# STM32U5A9xx register map
File version: 1.0
Registers are 32-bit, read-write, reset 0x0 unless marked. A register's access mark holds for its fields unless they carry their own. Offsets are from the block's base; [hi:lo] are bit positions; {n}, {i} and the like mark numbered series.

## DSI — DSI Controller
Base 0x40016C00
Same registers: DSI_S 0x50016C00
0x00 VR — DSI Host Version Register
  [31:0] VR — DSI Host Version 0x3134312A
0x04 CR — DSI Host Control Register
  [0] EN — DSI Host power up and reset
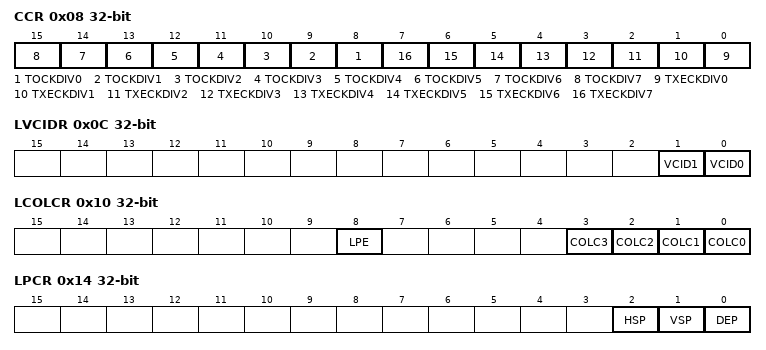
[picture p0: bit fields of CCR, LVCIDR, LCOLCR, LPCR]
0x08 CCR — DSI HOST Clock Control Register
  [n+8] TOCKDIV{n} (n=0..7), [n] TXECKDIV{n} (n=0..7)
0x0C LVCIDR — DSI Host LTDC VCID Register
  [1] VCID1, [0] VCID0
0x10 LCOLCR — DSI Host LTDC Color Coding Register
  [8] LPE — Loosely Packet Enable
  [n] COLC{n} (n=0..3)
0x14 LPCR — DSI Host LTDC Polarity Configuration Register
  [2] HSP — HSYNC Polarity
  [1] VSP — VSYNC Polarity
  [0] DEP — Data Enable Polarity
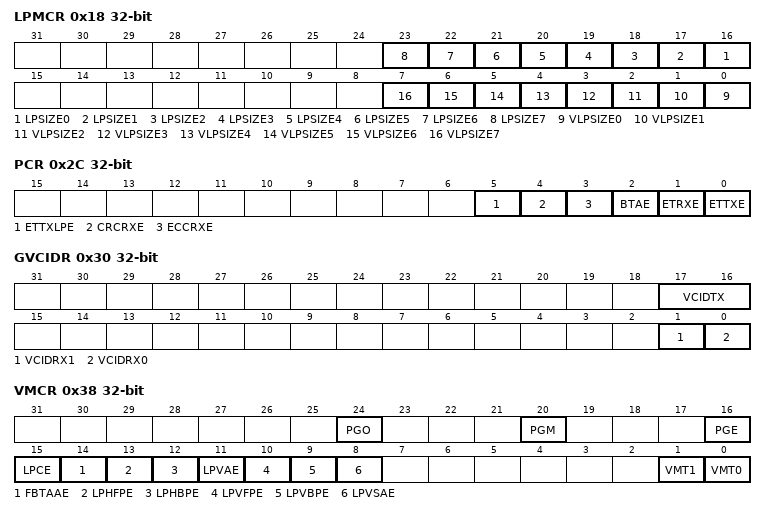
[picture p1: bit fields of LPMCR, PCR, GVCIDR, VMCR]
0x18 LPMCR — DSI Host Low-Power Mode Configuration Register
  [n+16] LPSIZE{n} (n=0..7), [n] VLPSIZE{n} (n=0..7)
0x2C PCR — DSI Host Protocol Configuration Register
  [5] ETTXLPE — EoTp Transmission in Low-Power Enable
  [4] CRCRXE — CRC Reception Enable
  [3] ECCRXE — ECC Reception Enable
  [2] BTAE — Bus Turn Around Enable
  [1] ETRXE — EoTp Reception Enable
  [0] ETTXE — EoTp Transmission Enable
0x30 GVCIDR — DSI Host Generic VCID Register
  [17:16] VCIDTX — Virtual Channel ID for Transmission
  [1] VCIDRX1
  [0] VCIDRX0
0x34 MCR — DSI Host Mode Configuration Register
  [0] CMDM — Command Mode
0x38 VMCR — DSI Host Video Mode Configuration Register
  [24] PGO — Pattern Generator Orientation
  [20] PGM — Pattern Generator Mode
  [16] PGE — Pattern Generator Enable
  [15] LPCE — Low-Power Command Enable
  [14] FBTAAE — Frame Bus-Turn-Around Acknowledge Enable
  [13] LPHFPE — Low-Power Horizontal Front-Porch Enable
  [12] LPHBPE — Low-Power Horizontal Back-Porch Enable
  [11] LPVAE — Low-Power Vertical Active Enable
  [10] LPVFPE — Low-power Vertical Front-porch Enable
  [9] LPVBPE — Low-power Vertical Back-Porch Enable
  [8] LPVSAE — Low-Power Vertical Sync Active Enable
  [1] VMT1
  [0] VMT0
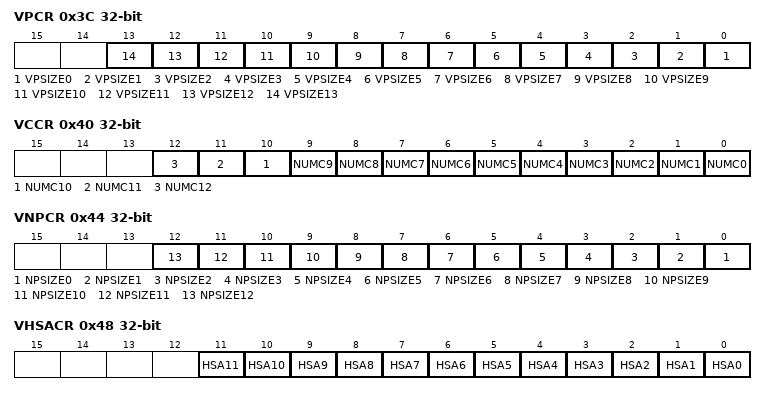
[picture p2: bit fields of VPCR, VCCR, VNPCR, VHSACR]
0x3C VPCR — DSI Host Video Packet Configuration Register
  [n] VPSIZE{n} (n=0..13)
0x40 VCCR — DSI Host Video Chunks Configuration Register
  [n] NUMC{n} (n=0..12)
0x44 VNPCR — DSI Host Video Null Packet Configuration Register
  [n] NPSIZE{n} (n=0..12)
0x48 VHSACR — DSI Host Video HSA Configuration Register
  [n] HSA{n} (n=0..11)
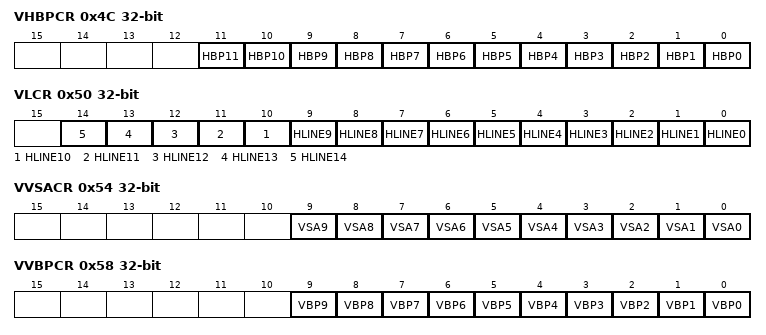
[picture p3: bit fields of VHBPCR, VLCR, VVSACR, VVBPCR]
0x4C VHBPCR — DSI Host Video HBP Configuration Register
  [n] HBP{n} (n=0..11)
0x50 VLCR — DSI Host Video Line Configuration Register
  [n] HLINE{n} (n=0..14)
0x54 VVSACR — DSI Host Video VSA Configuration Register
  [n] VSA{n} (n=0..9)
0x58 VVBPCR — DSI Host Video VBP Configuration Register
  [n] VBP{n} (n=0..9)
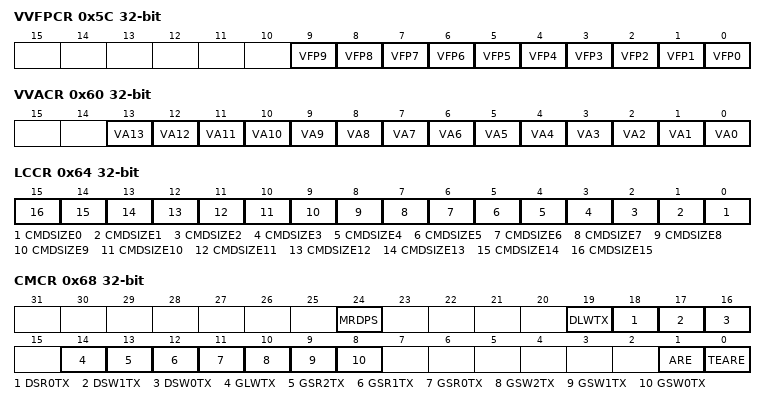
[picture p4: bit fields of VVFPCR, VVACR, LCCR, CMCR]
0x5C VVFPCR — DSI Host Video VFP Configuration Register
  [n] VFP{n} (n=0..9)
0x60 VVACR — DSI Host Video VA Configuration Register
  [n] VA{n} (n=0..13)
0x64 LCCR — DSI Host LTDC Command Configuration Register
  [n] CMDSIZE{n} (n=0..15)
0x68 CMCR — DSI Host Command Mode Configuration Register
  [24] MRDPS — Maximum Read Packet Size
  [19] DLWTX — DCS Long Write Transmission
  [18] DSR0TX — DCS Short Read Zero parameter Transmission
  [17] DSW1TX — DCS Short Read One parameter Transmission
  [16] DSW0TX — DCS Short Write Zero parameter Transmission
  [14] GLWTX — Generic Long Write Transmission
  [13] GSR2TX — Generic Short Read Two parameters Transmission
  [12] GSR1TX — Generic Short Read One parameters Transmission
  [11] GSR0TX — Generic Short Read Zero parameters Transmission
  [10] GSW2TX — Generic Short Write Two parameters Transmission
  [9] GSW1TX — Generic Short Write One parameters Transmission
  [8] GSW0TX — Generic Short Write Zero parameters Transmission
  [1] ARE — Acknowledge Request Enable
  [0] TEARE — Tearing Effect Acknowledge Request Enable
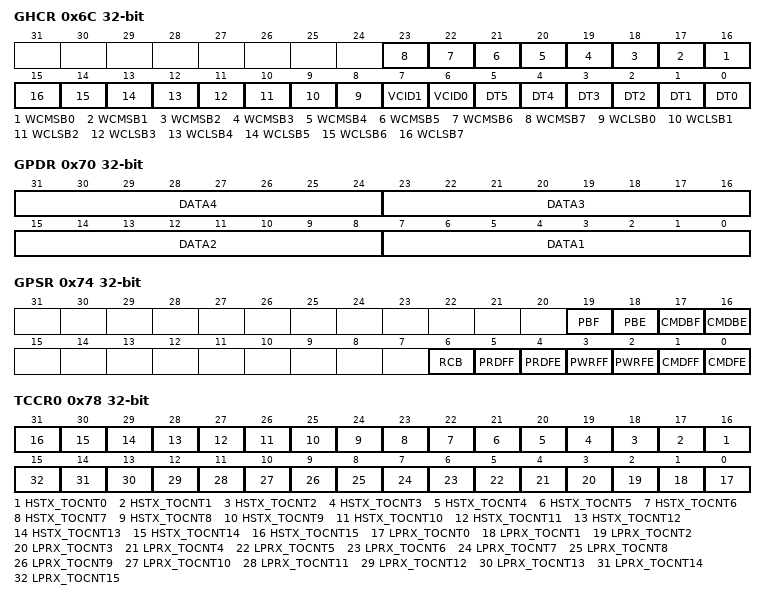
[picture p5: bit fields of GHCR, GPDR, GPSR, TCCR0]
0x6C GHCR — DSI Host Generic Header Configuration Register
  [n+16] WCMSB{n} (n=0..7), [n+8] WCLSB{n} (n=0..7), [7] VCID1, [6] VCID0, [n] DT{n} (n=0..5)
0x70 GPDR — DSI Host Generic Payload Data Register
  [8n-1:8n-8] DATA{n} (n=1..4) — Payload Byte {n}
0x74 GPSR — DSI Host Generic Packet Status Register
  [19] PBF — Payload Buffer Full
  [18] PBE — Payload Buffer Empty
  [17] CMDBF — Command Buffer Full
  [16] CMDBE — Command Buffer Empty
  [6] RCB — Read Command Busy
  [5] PRDFF — Payload Read FIFO Full
  [4] PRDFE — Payload Read FIFO Empty
  [3] PWRFF — Payload Write FIFO Full
  [2] PWRFE — Payload Write FIFO Empty
  [1] CMDFF — Command FIFO Full
  [0] CMDFE — Command FIFO Empty
0x78 TCCR0 — DSI Host Timeout Counter Configuration Register
  [n+16] HSTX_TOCNT{n} (n=0..15), [n] LPRX_TOCNT{n} (n=0..15)
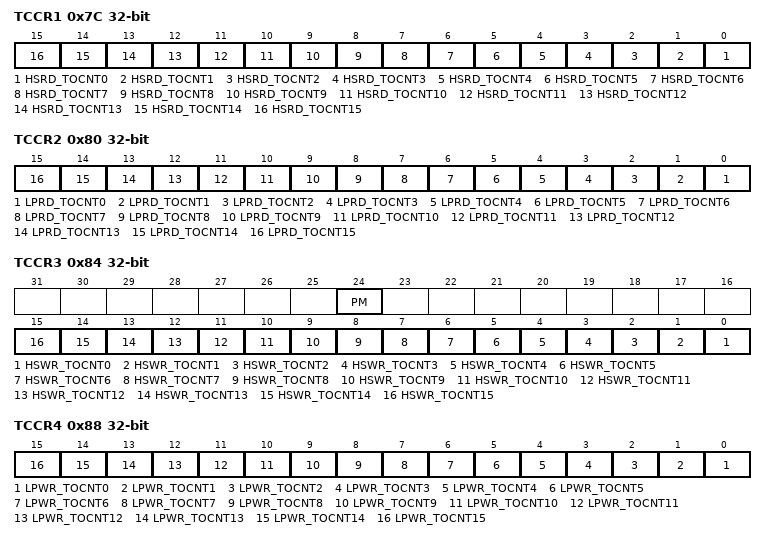
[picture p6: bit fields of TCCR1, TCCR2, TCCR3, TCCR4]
0x7C TCCR1 — DSI Host Timeout Counter Configuration Register
  [n] HSRD_TOCNT{n} (n=0..15)
0x80 TCCR2 — DSI Host Timeout Counter Configuration Register
  [n] LPRD_TOCNT{n} (n=0..15)
0x84 TCCR3 — DSI Host Timeout Counter Configuration Register
  [24] PM — Presp Mode
  [n] HSWR_TOCNT{n} (n=0..15)
0x88 TCCR4 — DSI Host Timeout Counter Configuration Register
  [n] LPWR_TOCNT{n} (n=0..15)
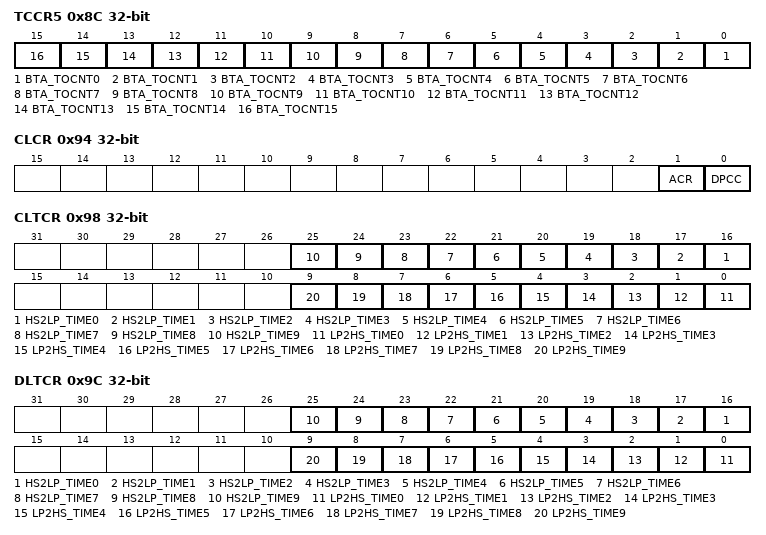
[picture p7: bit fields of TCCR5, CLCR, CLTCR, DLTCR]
0x8C TCCR5 — DSI Host Timeout Counter Configuration Register
  [n] BTA_TOCNT{n} (n=0..15)
0x94 CLCR — DSI Host Clock Lane Configuration Register
  [1] ACR — Automatic Clocklane Control
  [0] DPCC — D-PHY Clock Control
0x98 CLTCR — DSI Host Clock Lane Timer Configuration Register
  [n+16] HS2LP_TIME{n} (n=0..9), [n] LP2HS_TIME{n} (n=0..9)
0x9C DLTCR — DSI Host Data Lane Timer Configuration Register
  [n+16] HS2LP_TIME{n} (n=0..9), [n] LP2HS_TIME{n} (n=0..9)
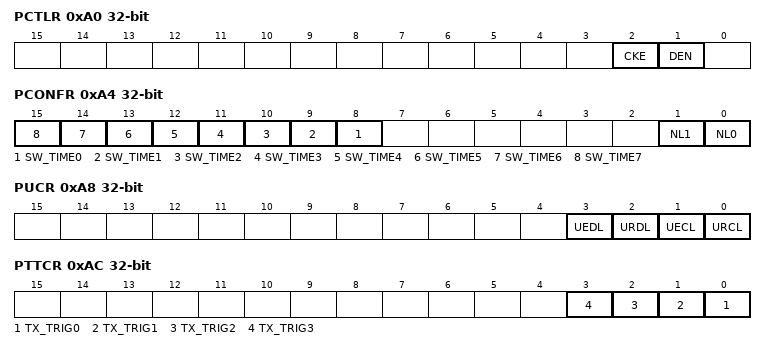
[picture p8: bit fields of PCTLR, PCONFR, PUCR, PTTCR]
0xA0 PCTLR — DSI Host PHY Control Register
  [2] CKE — Clock Enable
  [1] DEN — Digital Enable
0xA4 PCONFR — DSI Host PHY Configuration Register
  [n+8] SW_TIME{n} (n=0..7), [1] NL1, [0] NL0
0xA8 PUCR — DSI Host PHY ULPS Control Register
  [3] UEDL — ULPS Exit on Data Lane
  [2] URDL — ULPS Request on Data Lane
  [1] UECL — ULPS Exit on Clock Lane
  [0] URCL — ULPS Request on Clock Lane
0xAC PTTCR — DSI Host PHY TX Triggers Configuration Register
  [n] TX_TRIG{n} (n=0..3)
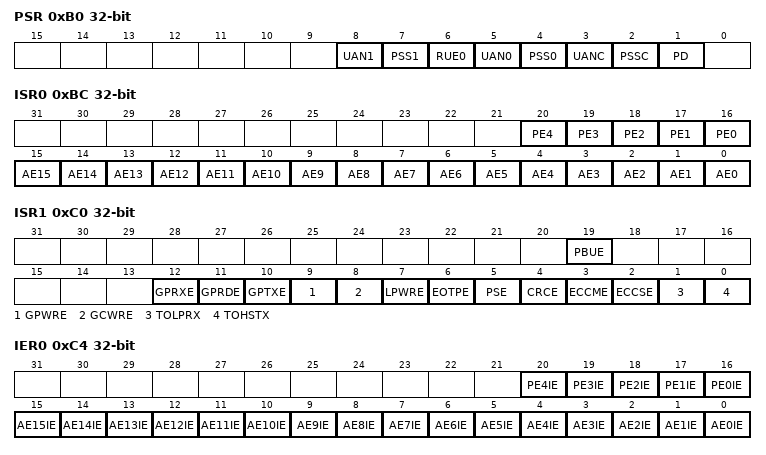
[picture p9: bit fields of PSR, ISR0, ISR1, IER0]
0xB0 PSR — DSI Host PHY Status Register
  [8] UAN1 — ULPS Active Not lane 1
  [7] PSS1 — PHY Stop State lane 1
  [6] RUE0 — RX ULPS Escape lane 0
  [5] UAN0 — ULPS Active Not lane 0
  [4] PSS0 — PHY Stop State lane 0
  [3] UANC — ULPS Active Not Clock lane
  [2] PSSC — PHY Stop State Clock lane
  [1] PD — PHY Direction
0xBC ISR0 — DSI Host Interrupt & Status Register
  [n+16] PE{n} (n=0..4) — PHY Error {n}
  [n] AE{n} (n=0..15) — Acknowledge Error {n}
0xC0 ISR1 — DSI Host Interrupt & Status Register
  [19] PBUE — Payload Buffer Underflow Error
  [12] GPRXE — Generic Payload Receive Error
  [11] GPRDE — Generic Payload Read Error
  [10] GPTXE — Generic Payload Transmit Error
  [9] GPWRE — Generic Payload Write Error
  [8] GCWRE — Generic Command Write Error
  [7] LPWRE — LTDC Payload Write Error
  [6] EOTPE — EoTp Error
  [5] PSE — Packet Size Error
  [4] CRCE — CRC Error
  [3] ECCME — ECC Multi-bit Error
  [2] ECCSE — ECC Single-bit Error
  [1] TOLPRX — Timeout Low-Power Reception
  [0] TOHSTX — Timeout High-Speed Transmission
0xC4 IER0 — DSI Host Interrupt Enable Register
  [n+16] PE{n}IE (n=0..4) — PHY Error {n} Interrupt Enable
  [n] AE{n}IE (n=0..15) — Acknowledge Error {n} Interrupt Enable
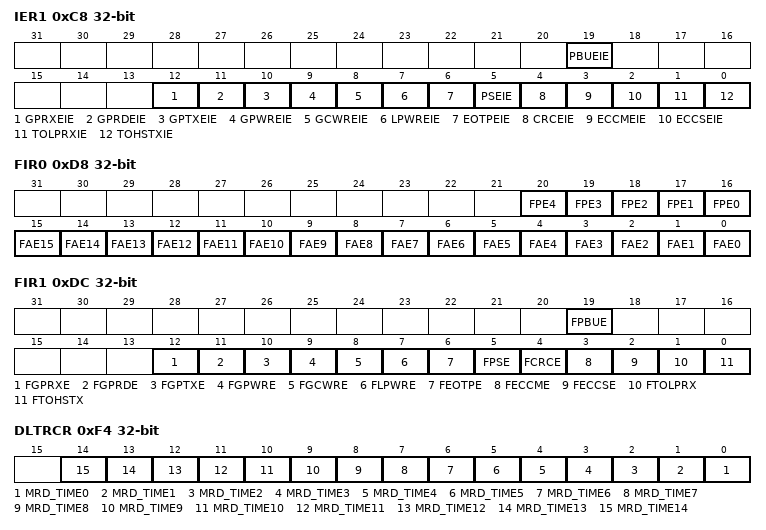
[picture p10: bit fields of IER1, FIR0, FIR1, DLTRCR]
0xC8 IER1 — DSI Host Interrupt Enable Register
  [19] PBUEIE — Payload Buffer Underflow Error Interrupt Enable
  [12] GPRXEIE — Generic Payload Receive Error Interrupt Enable
  [11] GPRDEIE — Generic Payload Read Error Interrupt Enable
  [10] GPTXEIE — Generic Payload Transmit Error Interrupt Enable
  [9] GPWREIE — Generic Payload Write Error Interrupt Enable
  [8] GCWREIE — Generic Command Write Error Interrupt Enable
  [7] LPWREIE — LTDC Payload Write Error Interrupt Enable
  [6] EOTPEIE — EoTp Error Interrupt Enable
  [5] PSEIE — Packet Size Error Interrupt Enable
  [4] CRCEIE — CRC Error Interrupt Enable
  [3] ECCMEIE — ECC Multi-bit Error Interrupt Enable
  [2] ECCSEIE — ECC Single-bit Error Interrupt Enable
  [1] TOLPRXIE — Timeout Low-Power Reception Interrupt Enable
  [0] TOHSTXIE — Timeout High-Speed Transmission Interrupt Enable
0xD8 FIR0 — DSI Host Force Interrupt Register
  [n+16] FPE{n} (n=0..4) — Force PHY Error {n}
  [n] FAE{n} (n=0..15) — Force Acknowledge Error {n}
0xDC FIR1 — DSI Host Force Interrupt Register
  [19] FPBUE — Force Payload Buffer Underflow Error
  [12] FGPRXE — Force Generic Payload Receive Error
  [11] FGPRDE — Force Generic Payload Read Error
  [10] FGPTXE — Force Generic Payload Transmit Error
  [9] FGPWRE — Force Generic Payload Write Error
  [8] FGCWRE — Force Generic Command Write Error
  [7] FLPWRE — Force LTDC Payload Write Error
  [6] FEOTPE — Force EoTp Error
  [5] FPSE — Force Packet Size Error
  [4] FCRCE — Force CRC Error
  [3] FECCME — Force ECC Multi-bit Error
  [2] FECCSE — Force ECC Single-bit Error
  [1] FTOLPRX — Force Timeout Low-Power Reception
  [0] FTOHSTX — Force Timeout High-Speed Transmission
0xF4 DLTRCR — DSI Host Data Lane Timer Read Configuration Register
  [n] MRD_TIME{n} (n=0..14)
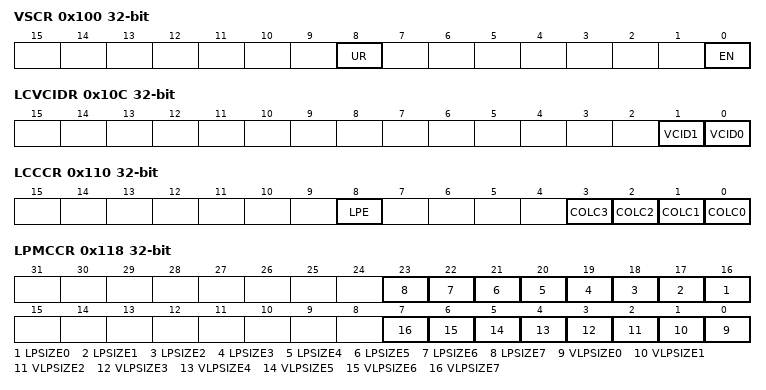
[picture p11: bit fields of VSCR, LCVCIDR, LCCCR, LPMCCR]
0x100 VSCR — DSI Host Video Shadow Control Register
  [8] UR — Update Register
  [0] EN — Enable
0x10C LCVCIDR — DSI Host LTDC Current VCID Register
  [1] VCID1, [0] VCID0
0x110 LCCCR — DSI Host LTDC Current Color Coding Register
  [8] LPE — Loosely Packed Enable
  [n] COLC{n} (n=0..3)
0x118 LPMCCR — DSI Host Low-power Mode Current Configuration Register
  [n+16] LPSIZE{n} (n=0..7), [n] VLPSIZE{n} (n=0..7)
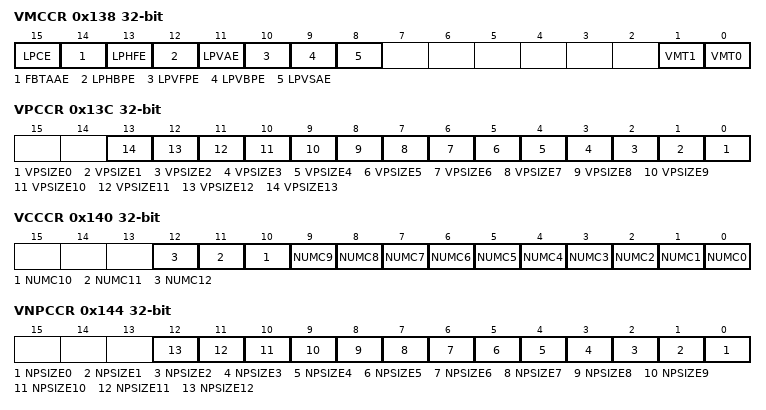
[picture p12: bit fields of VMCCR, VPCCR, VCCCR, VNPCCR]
0x138 VMCCR — DSI Host Video Mode Current Configuration Register
  [15] LPCE — Low-power Command Enable
  [14] FBTAAE — Frame BTA Acknowledge Enable
  [13] LPHFE — Low-power Horizontal Front-porch Enable
  [12] LPHBPE — Low-power Horizontal Back-porch Enable
  [11] LPVAE — Low-power Vertical Active Enable
  [10] LPVFPE — Low-power Vertical Front-porch Enable
  [9] LPVBPE — Low-power Vertical Back-porch Enable
  [8] LPVSAE — Low-power Vertical Sync time Enable
  [1] VMT1
  [0] VMT0
0x13C VPCCR — DSI Host Video Packet Current Configuration Register
  [n] VPSIZE{n} (n=0..13)
0x140 VCCCR — DSI Host Video Chunks Current Configuration Register
  [n] NUMC{n} (n=0..12)
0x144 VNPCCR — DSI Host Video Null Packet Current Configuration Register
  [n] NPSIZE{n} (n=0..12)
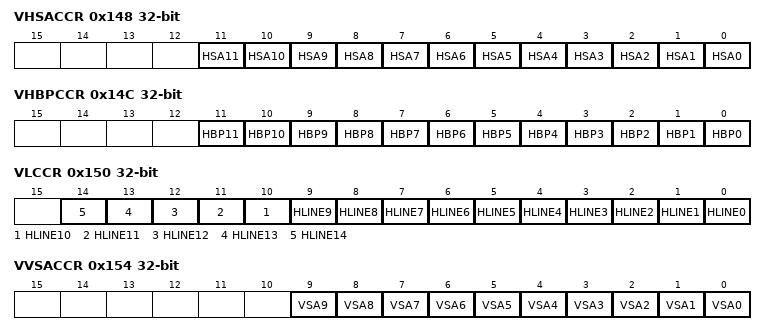
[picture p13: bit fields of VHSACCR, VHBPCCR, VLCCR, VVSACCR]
0x148 VHSACCR — DSI Host Video HSA Current Configuration Register
  [n] HSA{n} (n=0..11)
0x14C VHBPCCR — DSI Host Video HBP Current Configuration Register
  [n] HBP{n} (n=0..11)
0x150 VLCCR — DSI Host Video Line Current Configuration Register
  [n] HLINE{n} (n=0..14)
0x154 VVSACCR — DSI Host Video VSA Current Configuration Register
  [n] VSA{n} (n=0..9)
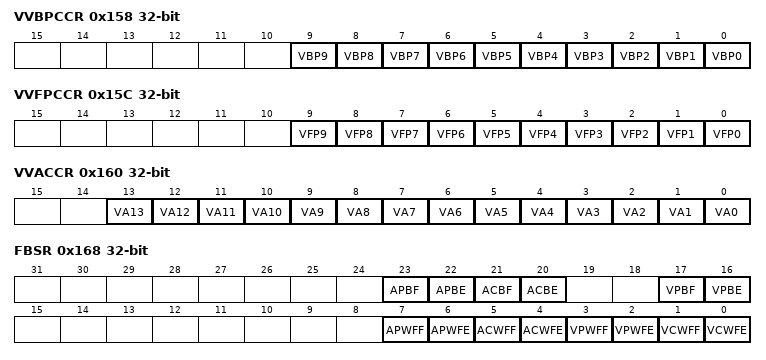
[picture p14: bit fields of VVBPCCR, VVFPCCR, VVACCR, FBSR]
0x158 VVBPCCR — DSI Host Video VBP Current Configuration Register
  [n] VBP{n} (n=0..9)
0x15C VVFPCCR — DSI Host Video VFP Current Configuration Register
  [n] VFP{n} (n=0..9)
0x160 VVACCR — DSI Host Video VA Current Configuration Register
  [n] VA{n} (n=0..13)
0x168 FBSR — DSI Host FIFO and Buffer Status Register
  [23] APBF — Adapted mode Payload Buffer Full
  [22] APBE — Adapted mode Payload Buffer Empty
  [21] ACBF — Adapted mode Command Buffer Full
  [20] ACBE — Adapted mode Command Buffer Empty
  [17] VPBF — Video mode Payload Buffer Full
  [16] VPBE — Video mode Payload Buffer Empty
  [7] APWFF — Adapted mode Payload Write FIFO Full
  [6] APWFE — Adapted mode Payload Write FIFO Empty
  [5] ACWFF — Adapted mode Command Write FIFO Full
  [4] ACWFE — Adapted mode Command Write FIFO Empty
  [3] VPWFF — Video mode Payload Write FIFO Full
  [2] VPWFE — Video mode Payload Write FIFO Empty
  [1] VCWFF — Video mode Command Write FIFO Full
  [0] VCWFE — Video mode Command Write FIFO Empty
0x400 WCFGR — DSI Wrapper Configuration Register
  [7] VSPOL — VSync Polarity
  [6] AR — Automatic Refresh
  [5] TEPOL — Tearing Effect Polarity
  [4] TESRC — Tearing Effect Source
  [3] COLMUX2
  [2] COLMUX1
  [1] COLMUX0
  [0] DSIM — DSI Mode
0x404 WCR — DSI Wrapper Control Register
  [3] DSIEN — DSI Enable
  [2] LTDCEN — LTDC Enable
  [1] SHTDN — Shutdown
  [0] COLM — Color Mode
0x408 WIER — DSI Wrapper Interrupt Enable Register
  [10] PLLUIE — PLL Unlock Interrupt Enable
  [9] PLLLIE — PLL Lock Interrupt Enable
  [1] ERIE — End of Refresh Interrupt Enable
  [0] TEIE — Tearing Effect Interrupt Enable
0x40C WISR — DSI Wrapper Interrupt and Status Register
  [10] PLLUIF — PLL Unlock Interrupt Flag
  [9] PLLLIF — PLL Lock Interrupt Flag
  [8] PLLLS — PLL Lock Status
  [2] BUSY — Busy Flag
  [1] ERIF — End of Refresh Interrupt Flag
  [0] TEIF — Tearing Effect Interrupt Flag
0x410 WIFCR — DSI Wrapper Interrupt Flag Clear Register
  [10] CPLLUIF — Clear PLL Unlock Interrupt Flag
  [9] CPLLLIF — Clear PLL Lock Interrupt Flag
  [1] CERIF — Clear End of Refresh Interrupt Flag
  [0] CTEIF — Clear Tearing Effect Interrupt Flag
0x418 WPCR0 — DSI Wrapper PHY Configuration Register 0
  [13] FTXSMDL — Force data lanes in TX stop mode
  [12] FTXSMCL — Force clock lane in TX stop mode
  [8] SWDL1 — Swap pins on data lane 2
  [7] SWDL0 — Swap pins on data lane 1
  [6] SWCL — Swap pins on clock lane
0x430 WRPCR — DSI Wrapper Regulator and PLL Control Register
  [29] BC
  [n+20] PLL_ODF{n} (n=0..8)
  [n+11] PLL_IDF{n} (n=0..8)
  [n+2] PLL_NDIV{n} (n=0..8)
  [0] PLLEN — PLL Enable
0x434 WPTR — DSI Wrapper PLL tuning register
  [n+12] LPF{n} (n=0..3), [n+8] CP{n} (n=0..3)
0x808 BCFGR — DSI Bias Configuration Register
  [6] PWRUP — Reference bias power up
0xC04 DPCBCR — D-PHY clock band control register
  [7:3] DPCBCR — clock band control register
0xC34 DPCSRCR — D-PHY clock slew rate control register
  [7:0] DPCSRCR — clock slew rate control register
0xC5C DPDL0HSOCR — D-PHY data Lane 0 HS
  [7:6] DPDL0HSOCR — data lane0 HS Prepare offset
  [5] HSPRPO1
  [4] HSPRPO0
0xC60 DPDL0LPXOCR — D-PHY data Lane 0 HS LPX
  [3:2] DPDL0LPXOCR — data lane 0 LPX Offset
  [1] LPXO1
  [0] LPXO0
0xC70 DPDL0BCR — D-PHY data Lane0 band control register
  [4:0] DPDL0BCR — data lane 0 band control register
0xCA0 DPDL0SRCR — D-PHY data Lane0 slew rate control register
  [7:0] DPDL0SRCR — data lane 0 slew rate control register
0xCF4 DPDL1HSOCR — D-PHY data Lane 1 HS
  [7:6] DPDL1HSOCR — data lane1 HS Prepare offset
  [5] HSPRPO01
  [4] HSPRPO00
0xCF8 DPDL1LPXOCR — D-PHY data Lane 1 HS LPX
  [3:2] DPDL1LPXOCR — data lane1 LPX Offset
  [1] LPXO1
  [0] LPXO0
0xD08 DPDL1BCR — D-PHY data Lane1 band control register
  [4:0] DPDL1BCR — data lane 1 band control register
0xD38 DPDL1SRCR — D-PHY data Lane1 slew rate control register
  [7:0] DPDL1SRCR — data lane 1 slew rate control register
